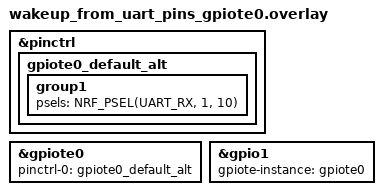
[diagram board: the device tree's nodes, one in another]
/*
 * Copyright (c) 2026 Nordic Semiconductor ASA
 *
 * SPDX-License-Identifier: LicenseRef-Nordic-5-Clause
 */

#include "wakeup_from_uart_pins.overlay"

/* Workaround, FUNC value is not important.
 * UICR/priphconf generator must parse pincontrol.
 * Otherwise, CTRLSEL is not set for input pin.
 */
&pinctrl {
	gpiote0_default_alt: gpiote0_default_alt {
		group1 {
			psels = <NRF_PSEL(UART_RX, 1, 10)>;
		};
	};
};

&gpiote0 {
	status = "okay";
	pinctrl-0 = <&gpiote0_default_alt>;
	pinctrl-names = "default";
};

&gpio1 {
	gpiote-instance = <&gpiote0>;
};
